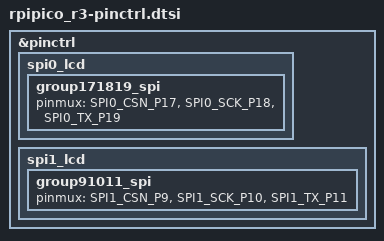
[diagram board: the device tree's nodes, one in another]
/*
 * Copyright (c) 2023-2026 TiaC Systems
 * SPDX-License-Identifier: Apache-2.0
 */

&pinctrl {
	spi0_lcd: spi0_lcd {
		group171819_spi {
			pinmux = <SPI0_CSN_P17>,	/* GP17: SPI0_CSN */
				 <SPI0_SCK_P18>,	/* GP18: SPI0_SCK */
				 <SPI0_TX_P19>;		/* GP19: SPI0_TX */
		};
		/* GP12: SPI0_RX not used for LCD only access */
	};
	spi1_lcd: spi1_lcd {
		group91011_spi {
			pinmux = <SPI1_CSN_P9>,		/* GP9: SPI1_CSN */
				 <SPI1_SCK_P10>,	/* GP10: SPI1_SCK */
				 <SPI1_TX_P11>;		/* GP11: SPI1_TX */
		};
		/* GP12: SPI1_RX not used for LCD only access */
	};
};
